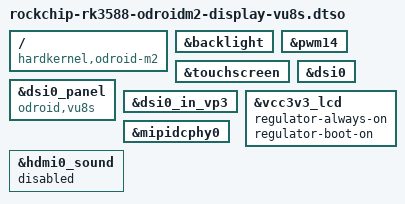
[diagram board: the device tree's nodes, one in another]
/dts-v1/;
/plugin/;

/ {
	compatible = "hardkernel,odroid-m2", "rockchip,rk3588s";

	fragment@0 {
		target = <&backlight>;

		__overlay__ {
			status = "okay";
		};
	};

	fragment@1 {
		target = <&pwm14>;

		__overlay__ {
			status = "okay";
		};
	};

	fragment@2 {
		target = <&touchscreen>;

		__overlay__ {
			status = "okay";
		};
	};

	fragment@3 {
		target = <&dsi0>;

		__overlay__ {
			status = "okay";
		};
	};

	fragment@4 {
		target = <&dsi0_panel>;

		__overlay__ {
			status = "okay";
			compatible = "odroid,vu8s";
		};
	};

	fragment@5 {
		target = <&dsi0_in_vp3>;

		__overlay__ {
			status = "okay";
		};
	};

	fragment@6 {
		target = <&vcc3v3_lcd>;

		__overlay__ {
			regulator-always-on;
			regulator-boot-on;
		};
	};

	fragment@7 {
		target = <&mipidcphy0>;

		__overlay__ {
			status = "okay";
		};
	};

	fragment@8 {
		target = <&hdmi0_sound>;

		__overlay__ {
			status = "disabled";
		};
	};
};
